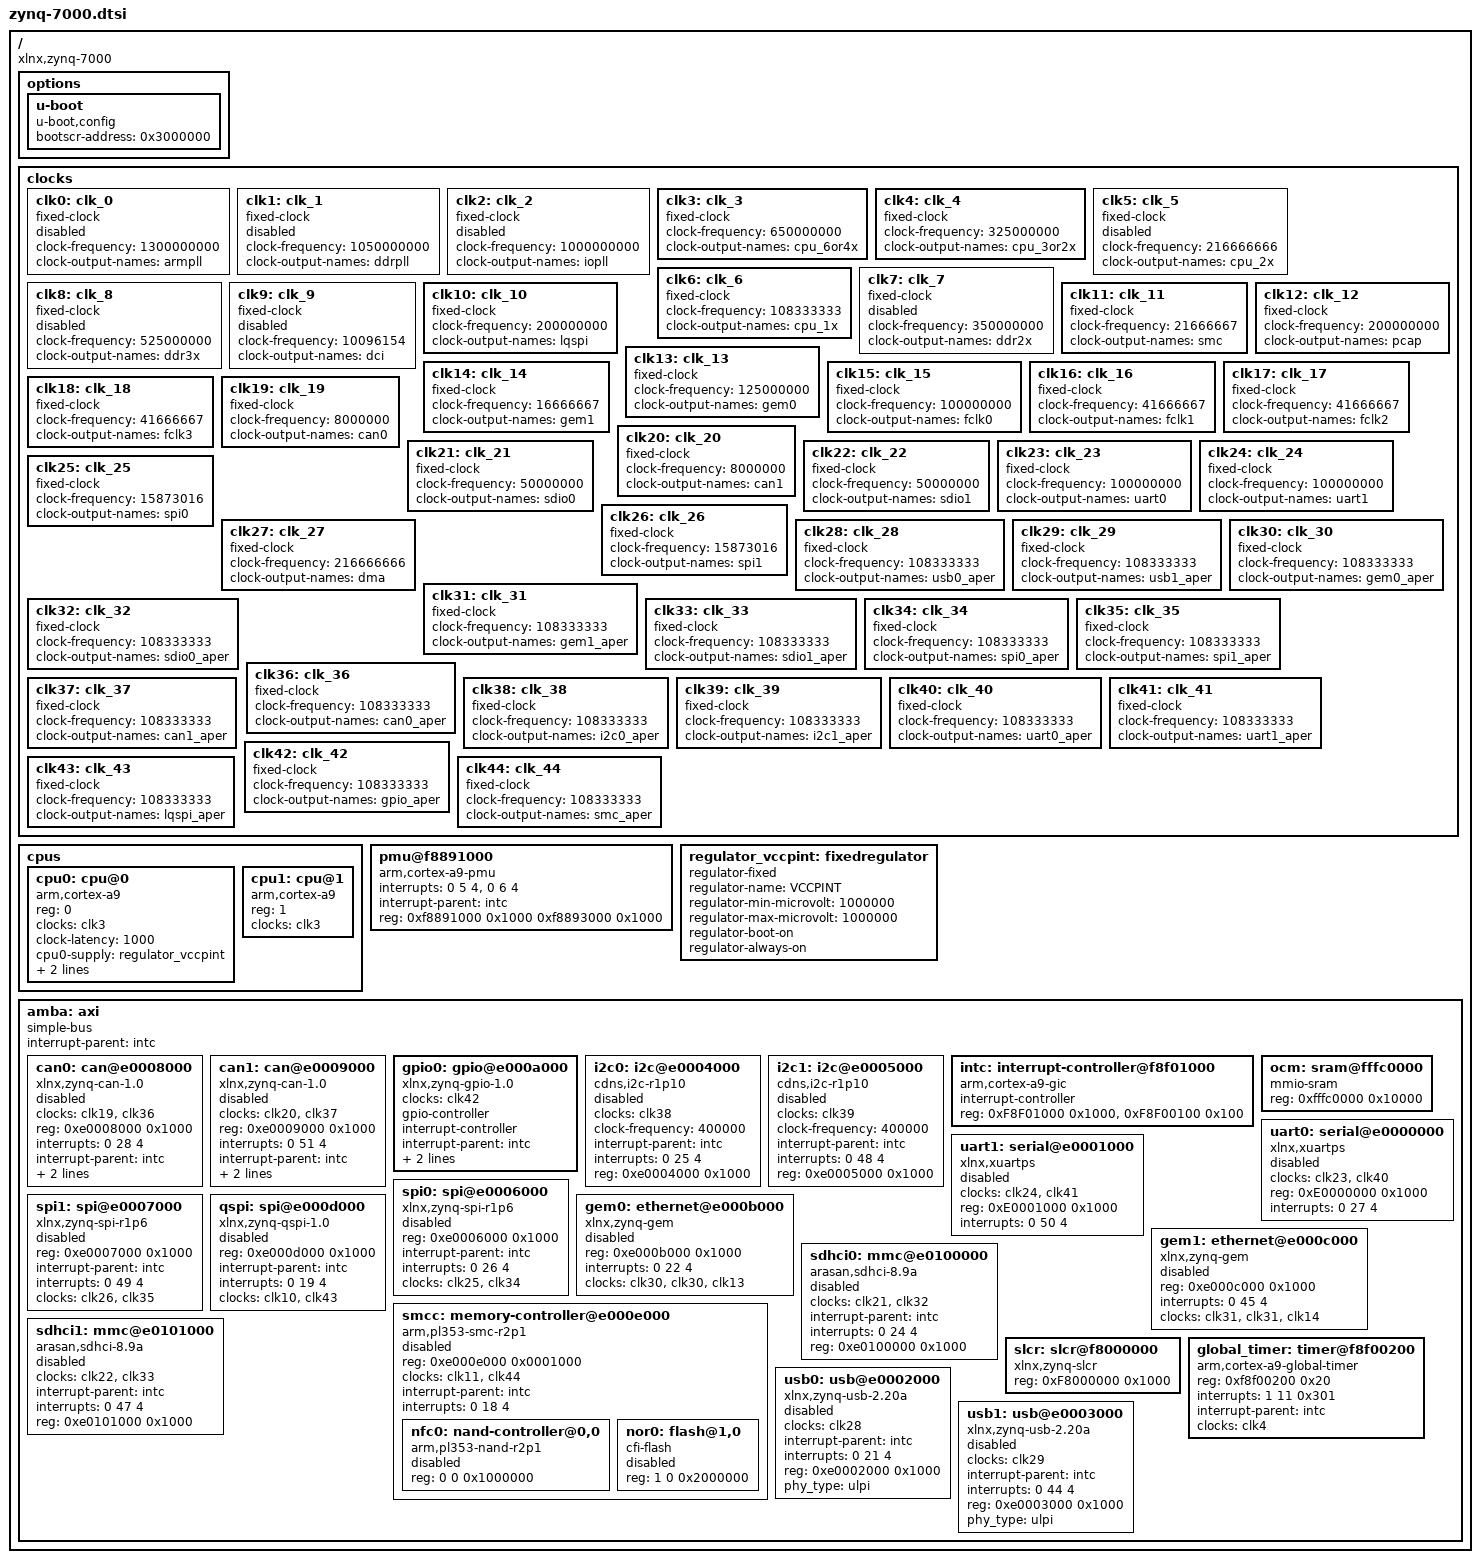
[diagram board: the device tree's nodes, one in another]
// SPDX-License-Identifier: GPL-2.0+
/*
 * Copyright (C) 2011-2022 Xilinx, Inc.
 * Copyright (C) 2022-2024 Advanced Micro Devices, Inc. All Rights Reserved.
 * Copyright (C) 2025 Zakaria Madaoui
 *
 * This software is licensed under the terms of the GNU General Public
 * License version 2, as published by the Free Software Foundation, and
 * may be copied, distributed, and modified under those terms.
 *
 * This program is distributed in the hope that it will be useful,
 * but WITHOUT ANY WARRANTY; without even the implied warranty of
 * MERCHANTABILITY or FITNESS FOR A PARTICULAR PURPOSE.  See the
 * GNU General Public License for more details.
 */

/ {
	#address-cells = <1>;
	#size-cells = <1>;
	compatible = "xlnx,zynq-7000";

	options {
		u-boot {
			compatible = "u-boot,config";
			bootscr-address = /bits/ 64 <0x3000000>;
		};
	};

	/* 
	 * The following clock frequencies have been taken from the output of `cat /sys/kernel/debug/clk/clk_summary` 
	 * when booting linux with normal device tree in secure world.
	*/
	clocks {
		bootph-all;

		clk0: clk_0 {
			status = "disabled"; /* not used by any other node, enable if needed */
            compatible = "fixed-clock";
            #clock-cells = <0>;
            clock-frequency = <1300000000>;
            clock-output-names = "armpll";
        };
		clk1: clk_1 {
			status = "disabled"; /* not used by any other node, enable if needed */
            compatible = "fixed-clock";
            #clock-cells = <0>;
            clock-frequency = <1050000000>;
            clock-output-names = "ddrpll";
        };

        clk2: clk_2 {
			status = "disabled"; /* not used by any other node, enable if needed */
            compatible = "fixed-clock";
            #clock-cells = <0>;
            clock-frequency = <1000000000>;
            clock-output-names = "iopll";
        };

        clk3: clk_3 {
            compatible = "fixed-clock";
            #clock-cells = <0>;
            clock-frequency = <650000000>;
            clock-output-names = "cpu_6or4x";
        };

        clk4: clk_4 {
            compatible = "fixed-clock";
            #clock-cells = <0>;
            clock-frequency = <325000000>;
            clock-output-names = "cpu_3or2x";
        };

		clk5: clk_5 {
			status = "disabled"; /* not used by any other node, enable if needed */
            compatible = "fixed-clock";
            #clock-cells = <0>;
            clock-frequency = <216666666>;
            clock-output-names = "cpu_2x";
        };

        clk6: clk_6 {
            compatible = "fixed-clock";
            #clock-cells = <0>;
            clock-frequency = <108333333>;
            clock-output-names = "cpu_1x";
        };

		clk7: clk_7 {
			status = "disabled"; /* not used by any other node, enable if needed */
            compatible = "fixed-clock";
            #clock-cells = <0>;
            clock-frequency = <350000000>;
            clock-output-names = "ddr2x";
        };

        clk8: clk_8 {
			status = "disabled"; /* not used by any other node, enable if needed */
            compatible = "fixed-clock";
            #clock-cells = <0>;
            clock-frequency = <525000000>;
            clock-output-names = "ddr3x";
        };

        clk9: clk_9 {
			status = "disabled"; /* not used by any other node, enable if needed */
            compatible = "fixed-clock";
            #clock-cells = <0>;
            clock-frequency = <10096154>;
            clock-output-names = "dci";
        };
        
        clk10: clk_10 {
            compatible = "fixed-clock";
            #clock-cells = <0>;
            clock-frequency = <200000000>;
            clock-output-names = "lqspi";
        };

		clk11: clk_11 {
			compatible = "fixed-clock";
			#clock-cells = <0>;
			clock-frequency = <21666667>;
			clock-output-names = "smc";
		};

		clk12: clk_12 {
			compatible = "fixed-clock";
			#clock-cells = <0>;
			clock-frequency = <200000000>;
			clock-output-names = "pcap";
		};

		clk13: clk_13 {
			compatible = "fixed-clock";
			#clock-cells = <0>;
			clock-frequency = <125000000>;
			clock-output-names = "gem0";
		};

		clk14: clk_14 {
			compatible = "fixed-clock";
			#clock-cells = <0>;
			clock-frequency = <16666667>;
			clock-output-names = "gem1";
		};

		clk15: clk_15 {
			compatible = "fixed-clock";
			#clock-cells = <0>;
			clock-frequency = <100000000>;
			clock-output-names = "fclk0";
		};

		clk16: clk_16 {
			compatible = "fixed-clock";
			#clock-cells = <0>;
			clock-frequency = <41666667>;
			clock-output-names = "fclk1";
		};

		clk17: clk_17 {
			compatible = "fixed-clock";
			#clock-cells = <0>;
			clock-frequency = <41666667>;
			clock-output-names = "fclk2";
		};

		clk18: clk_18 {
			compatible = "fixed-clock";
			#clock-cells = <0>;
			clock-frequency = <41666667>;
			clock-output-names = "fclk3";
		};

		clk19: clk_19 {
			compatible = "fixed-clock";
			#clock-cells = <0>;
			clock-frequency = <8000000>;
			clock-output-names = "can0";
		};

		clk20: clk_20 {
			compatible = "fixed-clock";
			#clock-cells = <0>;
			clock-frequency = <8000000>;
			clock-output-names = "can1";
		};

		clk21: clk_21 {
			compatible = "fixed-clock";
			#clock-cells = <0>;
			clock-frequency = <50000000>;
			clock-output-names = "sdio0";
		};

		clk22: clk_22 {
			compatible = "fixed-clock";
			#clock-cells = <0>;
			clock-frequency = <50000000>;
			clock-output-names = "sdio1";
		};

		clk23: clk_23 {
			compatible = "fixed-clock";
			#clock-cells = <0>;
			clock-frequency = <100000000>;
			clock-output-names = "uart0";
		};

		clk24: clk_24 {
			compatible = "fixed-clock";
			#clock-cells = <0>;
			clock-frequency = <100000000>;
			clock-output-names = "uart1";
		};

		clk25: clk_25 {
			compatible = "fixed-clock";
			#clock-cells = <0>;
			clock-frequency = <15873016>;
			clock-output-names = "spi0";
		};

		clk26: clk_26 {
			compatible = "fixed-clock";
			#clock-cells = <0>;
			clock-frequency = <15873016>;
			clock-output-names = "spi1";
		};

		clk27: clk_27 {
			compatible = "fixed-clock";
			#clock-cells = <0>;
			clock-frequency = <216666666>;
			clock-output-names = "dma";
		};

		clk28: clk_28 {
			compatible = "fixed-clock";
			#clock-cells = <0>;
			clock-frequency = <108333333>;
			clock-output-names = "usb0_aper";
		};

		clk29: clk_29 {
			compatible = "fixed-clock";
			#clock-cells = <0>;
			clock-frequency = <108333333>;
			clock-output-names = "usb1_aper";
		};

		clk30: clk_30 {
			compatible = "fixed-clock";
			#clock-cells = <0>;
			clock-frequency = <108333333>;
			clock-output-names = "gem0_aper";
		};

		clk31: clk_31 {
			compatible = "fixed-clock";
			#clock-cells = <0>;
			clock-frequency = <108333333>;
			clock-output-names = "gem1_aper";
		};

		clk32: clk_32 {
			compatible = "fixed-clock";
			#clock-cells = <0>;
			clock-frequency = <108333333>;
			clock-output-names = "sdio0_aper";
		};

		clk33: clk_33 {
			compatible = "fixed-clock";
			#clock-cells = <0>;
			clock-frequency = <108333333>;
			clock-output-names = "sdio1_aper";
		};

		clk34: clk_34 {
			compatible = "fixed-clock";
			#clock-cells = <0>;
			clock-frequency = <108333333>;
			clock-output-names = "spi0_aper";
		};

		clk35: clk_35 {
			compatible = "fixed-clock";
			#clock-cells = <0>;
			clock-frequency = <108333333>;
			clock-output-names = "spi1_aper";
		};

		clk36: clk_36 {
			compatible = "fixed-clock";
			#clock-cells = <0>;
			clock-frequency = <108333333>;
			clock-output-names = "can0_aper";
		};

		clk37: clk_37 {
			compatible = "fixed-clock";
			#clock-cells = <0>;
			clock-frequency = <108333333>;
			clock-output-names = "can1_aper";
		};

		clk38: clk_38 {
			compatible = "fixed-clock";
			#clock-cells = <0>;
			clock-frequency = <108333333>;
			clock-output-names = "i2c0_aper";
		};

		clk39: clk_39 {
			compatible = "fixed-clock";
			#clock-cells = <0>;
			clock-frequency = <108333333>;
			clock-output-names = "i2c1_aper";
		};

		clk40: clk_40 {
			compatible = "fixed-clock";
			#clock-cells = <0>;
			clock-frequency = <108333333>;
			clock-output-names = "uart0_aper";
		};

		clk41: clk_41 {
			compatible = "fixed-clock";
			#clock-cells = <0>;
			clock-frequency = <108333333>;
			clock-output-names = "uart1_aper";
		};

		clk42: clk_42 {
			compatible = "fixed-clock";
			#clock-cells = <0>;
			clock-frequency = <108333333>;
			clock-output-names = "gpio_aper";
		};

		clk43: clk_43 {
			compatible = "fixed-clock";
			#clock-cells = <0>;
			clock-frequency = <108333333>;
			clock-output-names = "lqspi_aper";
		};

		clk44: clk_44 {
			compatible = "fixed-clock";
			#clock-cells = <0>;
			clock-frequency = <108333333>;
			clock-output-names = "smc_aper";
		};

	};

	cpus {
		#address-cells = <1>;
		#size-cells = <0>;

		cpu0: cpu@0 {
			compatible = "arm,cortex-a9";
			device_type = "cpu";
			reg = <0>;
			clocks = <&clk3>;
			clock-latency = <1000>;
			cpu0-supply = <&regulator_vccpint>;
			operating-points = <
				/* kHz    uV */
				666667  1000000
				333334  1000000
			>;
		};

		cpu1: cpu@1 {
			compatible = "arm,cortex-a9";
			device_type = "cpu";
			reg = <1>;
			clocks = <&clk3>;
		};
	};

	pmu@f8891000 {
		compatible = "arm,cortex-a9-pmu";
		interrupts = <0 5 4>, <0 6 4>;
		interrupt-parent = <&intc>;
		reg = < 0xf8891000 0x1000 0xf8893000 0x1000 >;
	};

	regulator_vccpint: fixedregulator {
		compatible = "regulator-fixed";
		regulator-name = "VCCPINT";
		regulator-min-microvolt = <1000000>;
		regulator-max-microvolt = <1000000>;
		regulator-boot-on;
		regulator-always-on;
	};

	amba: axi {
		bootph-all;
		compatible = "simple-bus";
		#address-cells = <1>;
		#size-cells = <1>;
		interrupt-parent = <&intc>;
		ranges;

		

		can0: can@e0008000 {
			compatible = "xlnx,zynq-can-1.0";
			status = "disabled";
			clocks = <&clk19>, <&clk36>;
			clock-names = "can_clk", "pclk";
			reg = <0xe0008000 0x1000>;
			interrupts = <0 28 4>;
			interrupt-parent = <&intc>;
			tx-fifo-depth = <0x40>;
			rx-fifo-depth = <0x40>;
		};

		can1: can@e0009000 {
			compatible = "xlnx,zynq-can-1.0";
			status = "disabled";
			clocks = <&clk20>, <&clk37>;
			clock-names = "can_clk", "pclk";
			reg = <0xe0009000 0x1000>;
			interrupts = <0 51 4>;
			interrupt-parent = <&intc>;
			tx-fifo-depth = <0x40>;
			rx-fifo-depth = <0x40>;
		};

		gpio0: gpio@e000a000 {
			compatible = "xlnx,zynq-gpio-1.0";
			#gpio-cells = <2>;
			clocks = <&clk42>;
			gpio-controller;
			interrupt-controller;
			#interrupt-cells = <2>;
			interrupt-parent = <&intc>;
			interrupts = <0 20 4>;
			reg = <0xe000a000 0x1000>;
		};

		i2c0: i2c@e0004000 {
			compatible = "cdns,i2c-r1p10";
			status = "disabled";
			clocks = <&clk38>;
			clock-frequency = <400000>;
			interrupt-parent = <&intc>;
			interrupts = <0 25 4>;
			reg = <0xe0004000 0x1000>;
			#address-cells = <1>;
			#size-cells = <0>;
		};

		i2c1: i2c@e0005000 {
			compatible = "cdns,i2c-r1p10";
			status = "disabled";
			clocks = <&clk39>;
			clock-frequency = <400000>;
			interrupt-parent = <&intc>;
			interrupts = <0 48 4>;
			reg = <0xe0005000 0x1000>;
			#address-cells = <1>;
			#size-cells = <0>;
		};

		intc: interrupt-controller@f8f01000 {
			compatible = "arm,cortex-a9-gic";
			#interrupt-cells = <3>;
			interrupt-controller;
			reg = <0xF8F01000 0x1000>,
			      <0xF8F00100 0x100>;
		};

		
		ocm: sram@fffc0000 {
			compatible = "mmio-sram";
			reg = <0xfffc0000 0x10000>;
		};

		uart0: serial@e0000000 {
			compatible = "xlnx,xuartps", "cdns,uart-r1p8";
			status = "disabled";
			clocks = <&clk23>, <&clk40>;
			clock-names = "uart_clk", "pclk";
			reg = <0xE0000000 0x1000>;
			interrupts = <0 27 4>;
		};

		uart1: serial@e0001000 {
			compatible = "xlnx,xuartps", "cdns,uart-r1p8";
			status = "disabled";
			clocks = <&clk24>, <&clk41>;
			clock-names = "uart_clk", "pclk";
			reg = <0xE0001000 0x1000>;
			interrupts = <0 50 4>;
		};

		spi0: spi@e0006000 {
			compatible = "xlnx,zynq-spi-r1p6";
			reg = <0xe0006000 0x1000>;
			status = "disabled";
			interrupt-parent = <&intc>;
			interrupts = <0 26 4>;
			clocks = <&clk25>, <&clk34>;
			clock-names = "ref_clk", "pclk";
			#address-cells = <1>;
			#size-cells = <0>;
		};

		spi1: spi@e0007000 {
			compatible = "xlnx,zynq-spi-r1p6";
			reg = <0xe0007000 0x1000>;
			status = "disabled";
			interrupt-parent = <&intc>;
			interrupts = <0 49 4>;
			clocks = <&clk26>, <&clk35>;
			clock-names = "ref_clk", "pclk";
			#address-cells = <1>;
			#size-cells = <0>;
		};

		qspi: spi@e000d000 {
			compatible = "xlnx,zynq-qspi-1.0";
			reg = <0xe000d000 0x1000>;
			interrupt-parent = <&intc>;
			interrupts = <0 19 4>;
			clocks = <&clk10>, <&clk43>;
			clock-names = "ref_clk", "pclk";
			status = "disabled";
			#address-cells = <1>;
			#size-cells = <0>;
		};

		gem0: ethernet@e000b000 {
            compatible = "xlnx,zynq-gem", "cdns,gem";
			reg = <0xe000b000 0x1000>;
			status = "disabled";
			interrupts = <0 22 4>;
			clocks = <&clk30>, <&clk30>, <&clk13>;
			clock-names = "pclk", "hclk", "tx_clk";
			#address-cells = <1>;
			#size-cells = <0>;
		};

		gem1: ethernet@e000c000 {
            compatible = "xlnx,zynq-gem", "cdns,gem";
			reg = <0xe000c000 0x1000>;
			status = "disabled";
			interrupts = <0 45 4>;
			clocks = <&clk31>, <&clk31>, <&clk14>;
			clock-names = "pclk", "hclk", "tx_clk";
			#address-cells = <1>;
			#size-cells = <0>;
		};

		smcc: memory-controller@e000e000 {
			compatible = "arm,pl353-smc-r2p1", "arm,primecell";
			reg = <0xe000e000 0x0001000>;
			status = "disabled";
			clock-names = "memclk", "apb_pclk";
			clocks = <&clk11>, <&clk44>;
			ranges = <0x0 0x0 0xe1000000 0x1000000 /* Nand CS region */
				  0x1 0x0 0xe2000000 0x2000000 /* SRAM/NOR CS0 region */
				  0x2 0x0 0xe4000000 0x2000000>; /* SRAM/NOR CS1 region */
			#address-cells = <2>;
			#size-cells = <1>;
			interrupt-parent = <&intc>;
			interrupts = <0 18 4>;
			nfc0: nand-controller@0,0 {
				compatible = "arm,pl353-nand-r2p1";
				reg = <0 0 0x1000000>;
				status = "disabled";
				#address-cells = <0x1>;
				#size-cells = <0x0>;
			};
			nor0: flash@1,0 {
				status = "disabled";
				compatible = "cfi-flash";
				reg = <1 0 0x2000000>;
				#address-cells = <1>;
				#size-cells = <1>;
			};
		};

		sdhci0: mmc@e0100000 {
			compatible = "arasan,sdhci-8.9a";
			status = "disabled";
			clock-names = "clk_xin", "clk_ahb";
			clocks = <&clk21>, <&clk32>;
			interrupt-parent = <&intc>;
			interrupts = <0 24 4>;
			reg = <0xe0100000 0x1000>;
		};

		sdhci1: mmc@e0101000 {
			compatible = "arasan,sdhci-8.9a";
			status = "disabled";
			clock-names = "clk_xin", "clk_ahb";
			clocks = <&clk22>, <&clk33>;
			interrupt-parent = <&intc>;
			interrupts = <0 47 4>;
			reg = <0xe0101000 0x1000>;
		};

		slcr: slcr@f8000000 {
			bootph-all;
			#address-cells = <1>;
			#size-cells = <1>;
			compatible = "xlnx,zynq-slcr", "syscon", "simple-mfd";
			reg = <0xF8000000 0x1000>;
			ranges;	
		};

		global_timer: timer@f8f00200 {
			compatible = "arm,cortex-a9-global-timer";
			reg = <0xf8f00200 0x20>;
			interrupts = <1 11 0x301>;
			interrupt-parent = <&intc>;
			clocks = <&clk4>;
		};

		usb0: usb@e0002000 {
			compatible = "xlnx,zynq-usb-2.20a", "chipidea,usb2";
			status = "disabled";
			clocks = <&clk28>;
			interrupt-parent = <&intc>;
			interrupts = <0 21 4>;
			reg = <0xe0002000 0x1000>;
			phy_type = "ulpi";
		};

		usb1: usb@e0003000 {
			compatible = "xlnx,zynq-usb-2.20a", "chipidea,usb2";
			status = "disabled";
			clocks = <&clk29>;
			interrupt-parent = <&intc>;
			interrupts = <0 44 4>;
			reg = <0xe0003000 0x1000>;
			phy_type = "ulpi";
		};

	};
};
